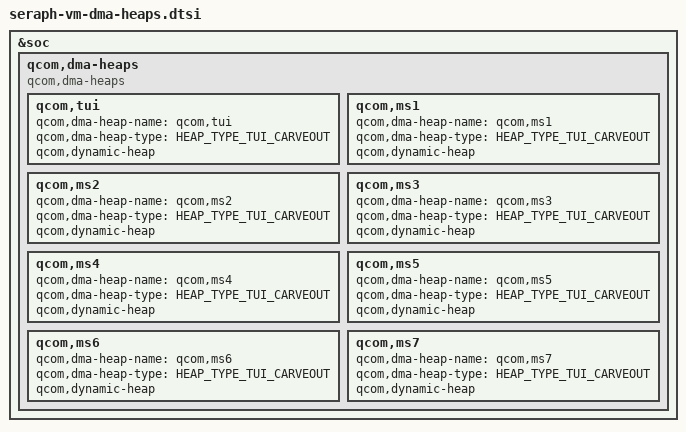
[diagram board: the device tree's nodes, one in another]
#include <dt-bindings/arm/msm/qcom_dma_heap_dt_constants.h>

&soc {
	qcom,dma-heaps {
		compatible = "qcom,dma-heaps";

		qcom,tui {
			qcom,dma-heap-name = "qcom,tui";
			qcom,dma-heap-type = <HEAP_TYPE_TUI_CARVEOUT>;
			qcom,dynamic-heap;
		};

		qcom,ms1 {
			qcom,dma-heap-name = "qcom,ms1";
			qcom,dma-heap-type = <HEAP_TYPE_TUI_CARVEOUT>;
			qcom,dynamic-heap;
		};

		qcom,ms2 {
			qcom,dma-heap-name = "qcom,ms2";
			qcom,dma-heap-type = <HEAP_TYPE_TUI_CARVEOUT>;
			qcom,dynamic-heap;
		};

		qcom,ms3 {
			qcom,dma-heap-name = "qcom,ms3";
			qcom,dma-heap-type = <HEAP_TYPE_TUI_CARVEOUT>;
			qcom,dynamic-heap;
		};

		qcom,ms4 {
			qcom,dma-heap-name = "qcom,ms4";
			qcom,dma-heap-type = <HEAP_TYPE_TUI_CARVEOUT>;
			qcom,dynamic-heap;
		};

		qcom,ms5 {
			qcom,dma-heap-name = "qcom,ms5";
			qcom,dma-heap-type = <HEAP_TYPE_TUI_CARVEOUT>;
			qcom,dynamic-heap;
		};

		qcom,ms6 {
			qcom,dma-heap-name = "qcom,ms6";
			qcom,dma-heap-type = <HEAP_TYPE_TUI_CARVEOUT>;
			qcom,dynamic-heap;
		};

		qcom,ms7 {
			qcom,dma-heap-name = "qcom,ms7";
			qcom,dma-heap-type = <HEAP_TYPE_TUI_CARVEOUT>;
			qcom,dynamic-heap;
		};
	};
};
